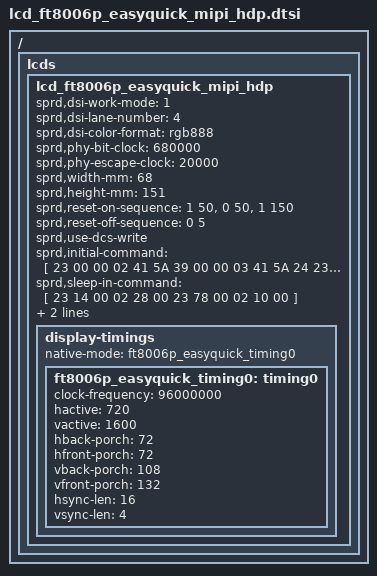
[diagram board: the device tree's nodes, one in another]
/ {
	fragment {
		target-path = "/";
		__overlay__ {
			lcds {
				lcd_ft8006p_easyquick_mipi_hdp: lcd_ft8006p_easyquick_mipi_hdp {

					sprd,dsi-work-mode = <1>; /* video burst mode*/
					sprd,dsi-lane-number = <4>;
					sprd,dsi-color-format = "rgb888";

					sprd,phy-bit-clock = <680000>;	/* kbps */
					sprd,phy-escape-clock = <20000>;/* kHz */

					sprd,width-mm = <68>;
					sprd,height-mm = <151>;

					sprd,reset-on-sequence = <1 50>, <0 50>, <1 150>;
					sprd,reset-off-sequence = <0 5>;

					sprd,use-dcs-write;

					sprd,initial-command = [
						23 00 00 02 41 5A
						39 00 00 03 41 5A 24
						23 00 00 02 90 5A
						39 00 00 03 41 5A 03
						39 00 00 03 80 C0 00
						39 00 00 03 41 5A 08
						39 00 00 04 80 C8 2C 01
						39 00 00 03 41 5A 09
						39 00 00 11 80 5A 51 B5 2A 6C E5 4A 01 40 62 0F 82 20 08 F0 B7
						39 00 00 11 90 00 24 42 0A E3 91 A4 F0 AF CD 66 20 41 A1 26 00
						39 00 00 11 A0 51 55 55 00 A0 4C 06 11 0D 60 5A FF FF 03 A5 E6
						39 00 00 11 B0 08 C9 16 64 0B 00 00 11 07 60 00 FF FF 03 FF 34
						39 00 00 09 C0 0C 3F 1F 9F 0F 00 08 00
						39 00 00 03 41 5A 0A
						39 00 00 11 80 FF 51 A3 02 00 0D 1A 2A 3B 4E 53 86 5E 97 A1 6F
						39 00 00 11 90 90 68 63 52 40 30 1D 0B 00 0D 1A 2A 3B 4E 53 86
						39 00 00 0E A0 5E 97 A1 6F 90 68 63 52 40 30 1D 0B 00
						39 00 00 03 41 5A 0B
						39 00 00 11 80 00 00 20 44 08 00 60 47 00 00 10 22 04 00 B0 23
						39 00 00 03 90 15 00
						39 00 00 03 41 5A 0C
						39 00 00 11 80 FA 68 68 01 32 64 20 08 00 60 15 00 50 15 56 51
						39 00 00 11 90 15 55 61 15 00 60 15 00 50 15 56 51 15 55 61 95
						39 00 00 11 A0 AB 18 00 05 00 05 00 05 80 4C 29 84 52 01 09 00
						39 00 00 03 B0 00 00
						39 00 00 03 41 5A 0D
						39 00 00 08 80 F0 B1 71 EF 4B C0 80
						39 00 00 03 41 5A 0E
						39 00 00 09 80 FF 01 55 55 23 88 88 1C
						39 00 00 03 41 5A 0F
						39 00 00 11 80 D1 07 6E C0 12 08 64 08 52 51 58 49 03 52 4C 4C
						39 00 00 11 90 68 68 68 4C 4C 7C 14 00 20 06 C2 00 04 06 0C 00
						39 00 00 05 A0 00 92 00 00
						39 00 00 03 41 5A 10
						39 00 00 11 80 00 00 03 E7 1F 17 10 48 80 AA D0 18 30 88 41 8A
						39 00 00 10 90 39 28 A9 C5 9A 7B F0 07 7E E0 07 7E 20 10 00
						39 00 00 03 41 5A 11
						39 00 00 11 80 46 77 03 40 CA F3 FF 83 30 08 C4 06 A1 D8 24 18
						39 00 00 11 90 30 C6 66 C1 80 31 15 CB E5 D2 68 6C 36 1D 04 C8
						39 00 00 11 A0 B0 D9 88 60 B0 81 40 1A 1B 48 63 03 B9 00 1C 80
						39 00 00 11 B0 50 30 00 E0 E1 01 00 28 0E 06 43 55 55 55 55 55
						39 00 00 11 C0 95 88 88 88 88 88 C8 08 86 C6 E3 81 00 20 00 21
						39 00 00 11 D0 42 88 00 00 00 00 40 00 00 31 04 41 06 00 00 00
						39 00 00 11 E0 00 92 04 00 92 04 00 00 00 00 92 04 00 85 11 0C
						39 00 00 10 F0 00 00 40 00 00 00 00 5E 4A 01 78 00 08 00 00
						39 00 00 03 41 5A 12
						39 00 00 11 80 00 00 00 00 00 02 03 00 00 00 00 02 03 01 41 37
						39 00 00 11 90 F1 E7 00 00 00 00 00 00 00 00 00 00 00 2D 23 05
						39 00 00 08 A0 FB 08 2D 23 05 FB 0C
						39 00 00 03 41 5A 13
						39 00 00 11 80 FD 0F 00 0C 00 00 00 00 01 08 01 1C 44 0C CE E7
						39 00 00 0F 90 62 0E 24 98 AC 21 01 00 D0 93 24 49 06 20
						39 00 00 03 41 5A 14
						39 00 00 11 80 01 02 41 36 E9 EF F7 FB FD 7E 01 00 00 90 C5 86
						39 00 00 11 90 3B 7D 60 0B 3C 12 02 9B E0 91 10 80 95 11 7C 00
						39 00 00 11 A0 00 FC 7E 00 00 E0 F7 03 00 20 83 B5 E2 F7 47 00
						39 00 00 11 B0 D8 89 DF 1F 01 00 00 00 00 44 32 24 2B 00 40 A1
						39 00 00 11 C0 50 78 03 EE B4 9C 51 1C 2F C0 9D 96 33 8A E3 15
						39 00 00 11 D0 B8 D3 72 46 71 BC 04 77 5A CE 28 8E D7 E0 4E CB
						39 00 00 11 E0 19 C5 F1 22 DC 69 39 A3 38 5E 85 3B 2D 67 14 C7
						39 00 00 11 F0 CB 70 A7 E5 8C E2 18 01 BF DF 08 00 00 00 00 00
						39 00 00 03 41 5A 15
						39 00 00 11 80 00 00 00 00 00 00 00 00 00 00 00 00 02 D9 E0 F7
						39 00 00 11 90 53 00 20 63 C5 A8 C5 07 C9 90 5D 31 6A F1 41 8C
						39 00 00 11 A0 78 00 00 00 00 00 00 00 00 00 00 00 00 00 00 00
						39 00 00 11 B0 00 00 00 00 00 00 00 00 13 00 F0 00 14 AA 55 4D
						39 00 00 11 C0 B3 6D DB D6 51 DA D6 10 A2 B6 6D DB B6 85 5A 53
						39 00 00 11 D0 35 DB B6 6D 01 A2 6D 11 46 6A DB B6 6D 5B A9 55
						39 00 00 11 E0 4D B3 6D DB 96 41 DA 96 00 A0 B6 6D DB B6 8D 5A
						39 00 00 11 F0 53 35 DB B6 6D 05 A3 6D 15 87 6A DB B6 6D 5B C0
						39 00 00 03 41 5A 16
						39 00 00 11 80 C3 43 41 01 00 00 00 00 00 00 00 00 00 00 00 00
						39 00 00 07 90 00 00 00 00 F0 20
						39 00 00 03 41 5A 18
						39 00 00 11 80 EF BD F7 DE 7B EF BD 07 08 08 0A 0C 0C 0C 0C 0C
						39 00 00 11 90 0C 0C 0C 5C 09 A8 AA AA AA AA AA AA AA AA AA 5A
						39 00 00 11 A0 59 59 59 59 59 59 59 59 59 59 59 09 04 FF 00 80
						39 00 00 10 B0 80 00 04 20 00 01 08 40 00 02 10 80 00 04 00
						39 00 00 03 41 5A 19
						39 00 00 11 80 C0 AF A3 9B 92 8D 8A 86 84 83 82 81 00 50 F6 CF
						39 00 00 11 90 FC 2F F3 EF CF BF 0F FF AF B5 71 0E 6C 4A 69 08
						39 00 00 05 A0 00 00 08 00
						39 00 00 03 41 5A 1A
						39 00 00 11 80 00 04 08 0C 00 10 14 18 1C 00 20 28 30 38 00 40
						39 00 00 11 90 48 50 58 00 60 68 70 78 00 80 88 90 98 00 A0 A8
						39 00 00 11 A0 B0 B8 00 C0 C8 D0 D8 00 E0 E8 F0 F8 00 FC FE FF
						39 00 00 11 B0 00 00 04 08 0C 00 10 14 18 1C 00 20 28 30 38 00
						39 00 00 11 C0 40 48 50 58 00 60 68 70 78 00 80 88 90 98 00 A0
						39 00 00 11 D0 A8 B0 B8 00 C0 C8 D0 D8 00 E0 E8 F0 F8 00 FC FE
						39 00 00 11 E0 FF 00 00 04 08 0C 00 10 14 18 1C 00 20 28 30 38
						39 00 00 11 F0 00 40 48 50 58 00 60 68 70 78 00 80 88 90 98 00
						39 00 00 03 41 5A 1B
						39 00 00 11 80 A0 A8 B0 B8 00 C0 C8 D0 D8 00 E0 E8 F0 F8 00 FC
						39 00 00 05 90 FE FF 00 00
						39 00 00 03 41 5A 20
						39 00 00 08 80 81 00 00 00 00 00 00
						39 00 00 03 41 5A 22
						39 00 00 0E 80 2D D3 00 55 55 55 55 55 55 55 55 9F 00
						39 00 00 03 41 5A 23
						39 00 00 11 80 01 05 00 05 00 00 00 00 00 00 00 00 00 00 00 00
						39 00 00 0D 90 FF 0F 00 00 00 03 00 00 00 FF 07 35
						39 00 00 03 41 5A 24
						39 00 00 11 80 00 03 00 FF FF 20 00 00 00 00 00 00 00 00 8C 34
						39 00 00 11 90 5A 5A 5A 55 00 00 00 00 00 00 00 00 00 00 00 00
						23 00 00 02 42 24
						23 00 00 02 90 00
						39 00 00 03 41 5A 2F
						23 00 00 02 19 00
						23 00 00 02 4C 03
						23 78 00 02 11 00
						23 14 00 02 29 00
						39 00 00 03 51 FF 0F
						23 00 00 02 53 24
						23 00 00 02 55 00

					];

					sprd,sleep-in-command = [
						23 14 00 02 28 00
						23 78 00 02 10 00
					];

					sprd,sleep-out-command = [
						23 78 00 23 11 00
						23 14 00 23 29 00
					];

					display-timings {
						native-mode = <&ft8006p_easyquick_timing0>;

						ft8006p_easyquick_timing0: timing0 {
							clock-frequency = <96000000>;
							hactive = <720>;
							vactive = <1600>;
							hback-porch = <72>;
							hfront-porch = <72>;
							vback-porch = <108>;
							vfront-porch = <132>;
							hsync-len = <16>;
							vsync-len = <4>;
						};
					};
				};
			};
		};
	};
};
